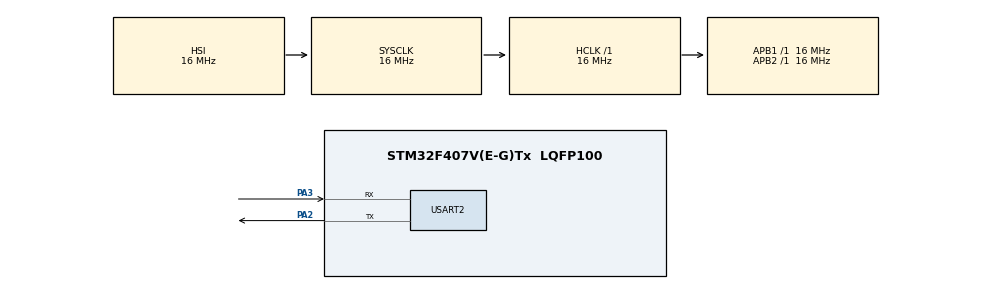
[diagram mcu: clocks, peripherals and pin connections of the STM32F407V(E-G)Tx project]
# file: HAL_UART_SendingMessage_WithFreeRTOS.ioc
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FREERTOS.Tasks01=defaultTask,0,128,StartDefaultTask,Default,NULL,Dynamic,NULL,NULL;myTask01,-3,128,StartTask01,Default,NULL,Dynamic,NULL,NULL;myTask02,-3,128,StartTask02,Default,NULL,Dynamic,NULL,NULL
Mcu.Family=STM32F4
Mcu.Name=STM32F407V(E-G)Tx
Mcu.Package=LQFP100
NVIC.PriorityGroup=NVIC_PRIORITYGROUP_4
NVIC.TIM7_IRQn=true\:15\:0\:false\:false\:true\:false\:false\:true\:true
NVIC.TimeBase=TIM7_IRQn
NVIC.TimeBaseIP=TIM7
PA2.Mode=Asynchronous
PA2.Signal=USART2_TX
PA3.Mode=Asynchronous
PA3.Signal=USART2_RX
ProjectManager.HeapSize=0x200
ProjectManager.StackSize=0x400
ProjectManager.TargetToolchain=Makefile
RCC.AHBFreq_Value=16000000
RCC.APB1Freq_Value=16000000
RCC.APB2Freq_Value=16000000
RCC.CortexFreq_Value=16000000
RCC.HSE_VALUE=25000000
RCC.HSI_VALUE=16000000
RCC.LSE_VALUE=32768
RCC.SYSCLKFreq_VALUE=16000000
RCC.VCOOutputFreq_Value=192000000
USART2.VirtualMode=VM_ASYNC
VP_FREERTOS_VS_CMSIS_V1.Mode=CMSIS_V1
VP_SYS_VS_tim7.Mode=TIM7
board=custom

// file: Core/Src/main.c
/* USER CODE BEGIN Header */
/**
  ******************************************************************************
  * @file           : main.c
  * @brief          : Main program body
  ******************************************************************************
  * @attention
  *
  * Copyright (c) 2026 STMicroelectronics.
  * All rights reserved.
  *
  * This software is licensed under terms that can be found in the LICENSE file
  * in the root directory of this software component.
  * If no LICENSE file comes with this software, it is provided AS-IS.
  *
  ******************************************************************************
  */
/* USER CODE END Header */
#include "main.h"
#include "cmsis_os.h"

/* USER CODE BEGIN Includes */
#include "stdio.h"
#include "stdbool.h"
#include "SEGGER_SYSVIEW.h"
#include <string.h>

/* USER CODE END Includes */

UART_HandleTypeDef huart2;

TaskHandle_t defaultTaskHandle = NULL;
TaskHandle_t myTask01Handle = NULL;
TaskHandle_t myTask02Handle = NULL;
/* USER CODE BEGIN PV */
int _write(int32_t file, uint8_t *ptr, int32_t len){

  for (int i = 0; i < len; i++)
  {
    ITM_SendChar((*ptr++));
  }
  return len;
}

bool taskFlag = 1;
// bool task1Flag = 1;
// bool task2Flag = 0;
/* USER CODE END PV */

void SystemClock_Config(void);
static void MX_GPIO_Init(void);
static void MX_USART2_UART_Init(void);
void StartDefaultTask(void * argument);
void StartTask01(void * argument);
void StartTask02(void * argument);

int main(void)
{

  /* USER CODE BEGIN 1 */
  CoreDebug->DEMCR |= CoreDebug_DEMCR_TRCENA_Msk;
  DWT->CYCCNT = 0;
  DWT->CTRL |= DWT_CTRL_CYCCNTENA_Msk;

  /* USER CODE END 1 */

  /* MCU Configuration--------------------------------------------------------*/

  /* Reset of all peripherals, Initializes the Flash interface and the Systick. */
  HAL_Init();

  /* USER CODE BEGIN Init */
  HAL_NVIC_SetPriorityGrouping(NVIC_PRIORITYGROUP_4);
  // setvbuf(stdout, NULL, _IONBF, 0);

  /* USER CODE END Init */

  /* Configure the system clock */
  SystemClock_Config();

  /* Initialize all configured peripherals */
  MX_GPIO_Init();
  MX_USART2_UART_Init();
  /* USER CODE BEGIN 2 */
  SEGGER_SYSVIEW_Conf();

  /* USER CODE END 2 */

  /* Create the thread(s) */
  /* definition and creation of defaultTask */
  // osThreadDef(defaultTask, StartDefaultTask, osPriorityNormal, 0, 128);
  // defaultTaskHandle = osThreadCreate(osThread(defaultTask), NULL);
  xTaskCreate(StartDefaultTask, "default", 128, NULL, 1, &defaultTaskHandle);

  /* definition and creation of myTask01 */
  // osThreadDef(myTask01, StartTask01, osPriorityIdle, 0, 128);
  // myTask01Handle = osThreadCreate(osThread(myTask01), NULL);
  xTaskCreate(StartTask01, "task1", 128, NULL, 1, &myTask01Handle);

  /* definition and creation of myTask02 */
  xTaskCreate(StartTask02, "task2", 128, NULL, 1, &myTask02Handle);

  /* Start scheduler */
  vTaskStartScheduler();
  /* We should never get here as control is now taken by the scheduler */

  /* Infinite loop */
  while (1)
  {

  }
}

void SystemClock_Config(void)
{
  RCC_OscInitTypeDef RCC_OscInitStruct = {0};
  RCC_ClkInitTypeDef RCC_ClkInitStruct = {0};

  /** Configure the main internal regulator output voltage
  */
  __HAL_RCC_PWR_CLK_ENABLE();
  __HAL_PWR_VOLTAGESCALING_CONFIG(PWR_REGULATOR_VOLTAGE_SCALE1);

  /** Initializes the RCC Oscillators according to the specified parameters
  * in the RCC_OscInitTypeDef structure.
  */
  RCC_OscInitStruct.OscillatorType = RCC_OSCILLATORTYPE_HSI;
  RCC_OscInitStruct.HSIState = RCC_HSI_ON;
  RCC_OscInitStruct.HSICalibrationValue = RCC_HSICALIBRATION_DEFAULT;
  RCC_OscInitStruct.PLL.PLLState = RCC_PLL_NONE;
  if (HAL_RCC_OscConfig(&RCC_OscInitStruct) != HAL_OK)
  {
    Error_Handler();
  }

  /** Initializes the CPU, AHB and APB buses clocks
  */
  RCC_ClkInitStruct.ClockType = RCC_CLOCKTYPE_HCLK|RCC_CLOCKTYPE_SYSCLK
                              |RCC_CLOCKTYPE_PCLK1|RCC_CLOCKTYPE_PCLK2;
  RCC_ClkInitStruct.SYSCLKSource = RCC_SYSCLKSOURCE_HSI;
  RCC_ClkInitStruct.AHBCLKDivider = RCC_SYSCLK_DIV1;
  RCC_ClkInitStruct.APB1CLKDivider = RCC_HCLK_DIV1;
  RCC_ClkInitStruct.APB2CLKDivider = RCC_HCLK_DIV1;

  if (HAL_RCC_ClockConfig(&RCC_ClkInitStruct, FLASH_LATENCY_0) != HAL_OK)
  {
    Error_Handler();
  }
}

static void MX_USART2_UART_Init(void)
{

  huart2.Instance = USART2;
  huart2.Init.BaudRate = 115200;
  huart2.Init.WordLength = UART_WORDLENGTH_8B;
  huart2.Init.StopBits = UART_STOPBITS_1;
  huart2.Init.Parity = UART_PARITY_NONE;
  huart2.Init.Mode = UART_MODE_TX_RX;
  huart2.Init.HwFlowCtl = UART_HWCONTROL_NONE;
  huart2.Init.OverSampling = UART_OVERSAMPLING_16;
  if (HAL_UART_Init(&huart2) != HAL_OK)
  {
    Error_Handler();
  }

}

static void MX_GPIO_Init(void)
{

  /* GPIO Ports Clock Enable */
  __HAL_RCC_GPIOA_CLK_ENABLE();

}

// void StartDefaultTask(void const * argument)
// {
//   /* USER CODE BEGIN 5 */
//   /* Infinite loop */
//   for(;;)
//   {
//     osDelay(1);
//   }
//   /* USER CODE END 5 */
// }

// /* USER CODE BEGIN Header_StartTask01 */
// /**
// * @brief Function implementing the myTask01 thread.
// * @param argument: Not used
// * @retval None
// */
// /* USER CODE END Header_StartTask01 */
// void StartTask01(void const * argument)
// {
//   /* USER CODE BEGIN StartTask01 */
//   /* Infinite loop */
//   for(;;)
//   {
//     if (task1Flag)
//     {
//       task2Flag = 0;
//       const *message  = "test\r\n";
//       HAL_UART_Transmit(&huart2, (uint8_t *)message, strlen(message), HAL_MAX_DELAY);
//       task2Flag = 1;
//       task1Flag = 0;
//     }

//   }
//   /* USER CODE END StartTask01 */
// }
void StartDefaultTask(void * argument)
{
  for(;;)
  {
    osDelay(1);
  }
}

void StartTask01(void * argument)
{
  /* USER CODE BEGIN StartTask01 */
  /* Infinite loop */
  for(;;)
  {
    if (taskFlag)
    {
      taskFlag = 0;
      const char *message  = "test\r\n";
      //HAL_UART_Transmit(&huart2, (uint8_t *)message, strlen(message), 100);
      taskFlag = 1;
      taskYIELD();
      vTaskDelay(1);
    }

  }
  /* USER CODE END StartTask01 */
}

void StartTask02(void * argument)
{
  /* USER CODE BEGIN StartTask02 */
  /* Infinite loop */
  for(;;)
  {
    if (taskFlag)
    {
      taskFlag = 0;
      const char *message  = "deneme\r\n";
      //HAL_UART_Transmit(&huart2, (uint8_t *)message, strlen(message), 100);
      taskFlag = 1;
      taskYIELD();
      vTaskDelay(1);

    }

  }
  /* USER CODE END StartTask02 */
}

void HAL_TIM_PeriodElapsedCallback(TIM_HandleTypeDef *htim)
{
  if (htim->Instance == TIM7)
  {
    HAL_IncTick();
  }
}

void Error_Handler(void)
{
  __disable_irq();
  while (1)
  {
  }
}
